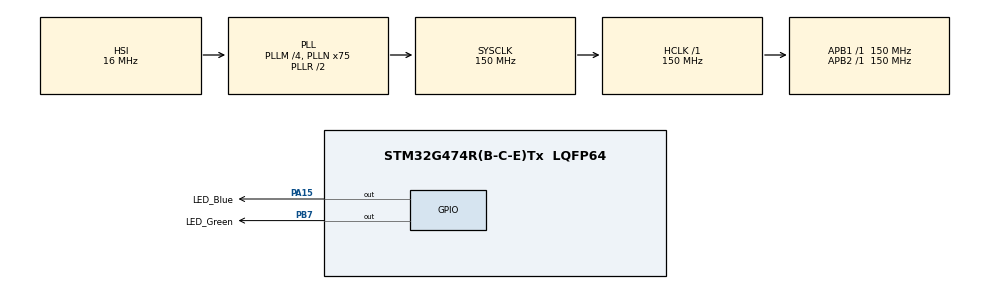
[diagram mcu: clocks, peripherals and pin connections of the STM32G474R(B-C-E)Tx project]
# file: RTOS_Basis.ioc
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FREERTOS.Tasks01=defaultTask,24,128,StartDefaultTask,Default,NULL,Dynamic,NULL,NULL
Mcu.Family=STM32G4
Mcu.Name=STM32G474R(B-C-E)Tx
Mcu.Package=LQFP64
NVIC.PriorityGroup=NVIC_PRIORITYGROUP_4
NVIC.TIM6_DAC_IRQn=true\:15\:0\:false\:false\:true\:false\:false\:true\:true
NVIC.TimeBase=TIM6_DAC_IRQn
NVIC.TimeBaseIP=TIM6
PA15.GPIO_Label=LED_Blue
PA15.Signal=GPIO_Output
PB7.GPIO_Label=LED_Green
PB7.Signal=GPIO_Output
ProjectManager.HeapSize=0x200
ProjectManager.StackSize=0x400
ProjectManager.TargetToolchain=STM32CubeIDE
RCC.ADC12Freq_Value=150000000
RCC.ADC345Freq_Value=150000000
RCC.AHBFreq_Value=150000000
RCC.APB1Freq_Value=150000000
RCC.APB1TimFreq_Value=150000000
RCC.APB2Freq_Value=150000000
RCC.APB2TimFreq_Value=150000000
RCC.CortexFreq_Value=150000000
RCC.EXTERNAL_CLOCK_VALUE=12288000
RCC.HCLKFreq_Value=150000000
RCC.HSE_VALUE=8000000
RCC.HSI48_VALUE=48000000
RCC.HSI_VALUE=16000000
RCC.LSE_VALUE=32768
RCC.PLLM=RCC_PLLM_DIV4
RCC.PLLN=75
RCC.SYSCLKFreq_VALUE=150000000
RCC.SYSCLKSource=RCC_SYSCLKSOURCE_PLLCLK
RCC.USBFreq_Value=150000000
RCC.VCOOutputFreq_Value=300000000
VP_FREERTOS_VS_CMSIS_V2.Mode=CMSIS_V2
VP_SYS_VS_DBSignals.Mode=DisableDeadBatterySignals
VP_SYS_VS_tim6.Mode=TIM6
board=custom

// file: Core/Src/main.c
/* USER CODE BEGIN Header */
/**
  ******************************************************************************
  * @file           : main.c
  * @brief          : Main program body
  ******************************************************************************
  * @attention
  *
  * Copyright (c) 2023 STMicroelectronics.
  * All rights reserved.
  *
  * This software is licensed under terms that can be found in the LICENSE file
  * in the root directory of this software component.
  * If no LICENSE file comes with this software, it is provided AS-IS.
  *
  ******************************************************************************
  */
/* USER CODE END Header */
#include "main.h"
#include "cmsis_os.h"

/* Definitions for defaultTask */
osThreadId_t defaultTaskHandle;
const osThreadAttr_t defaultTask_attributes = {
  .name = "defaultTask",
  .priority = (osPriority_t) osPriorityNormal,
  .stack_size = 128 * 4
};
/* USER CODE BEGIN PV */
#define DWT_CTRL (*(volatile uint32_t*) 0xE0001000)		// Bit 0 in this register can enable/disable the DWT_CYCCNT register
/* USER CODE END PV */

void SystemClock_Config(void);
static void MX_GPIO_Init(void);
void StartDefaultTask(void *argument);

/* USER CODE BEGIN PFP */
void vTaskLedBlue(void *pvParameters);
void vTaskLedGreen(void *pvParameters);
/* USER CODE END PFP */

int main(void)
{

  /* MCU Configuration--------------------------------------------------------*/

  /* Reset of all peripherals, Initializes the Flash interface and the Systick. */
  HAL_Init();

  /* Configure the system clock */
  SystemClock_Config();

  /* Initialize all configured peripherals */
  MX_GPIO_Init();

  /* Init scheduler */
  osKernelInitialize();

  /* Create the thread(s) */
  /* creation of defaultTask */
  //defaultTaskHandle = osThreadNew(StartDefaultTask, NULL, &defaultTask_attributes);

  /* USER CODE BEGIN RTOS_THREADS */
  // Enable the DWT_CYCCNT register (the cycle counter, to enable SEGGER time stamps)
  DWT_CTRL |= (1 << 0);

  SEGGER_SYSVIEW_Conf();
  SEGGER_SYSVIEW_Start();

  /* add threads, ... */
  // Blue LED task
  if((xTaskCreate(vTaskLedBlue, "Task LED Blue", configMINIMAL_STACK_SIZE, NULL, 1, NULL)) != pdTRUE)
  {

  }

  // Green LED task
  if((xTaskCreate(vTaskLedGreen, "Task LED Green", configMINIMAL_STACK_SIZE, NULL, 1, NULL)) != pdTRUE)
  {

  }
  /* USER CODE END RTOS_THREADS */

  /* Start scheduler */
  osKernelStart();

  /* We should never get here as control is now taken by the scheduler */
  /* Infinite loop */
  while (1)
  {

  }
}

void SystemClock_Config(void)
{
  RCC_OscInitTypeDef RCC_OscInitStruct = {0};
  RCC_ClkInitTypeDef RCC_ClkInitStruct = {0};

  /** Configure the main internal regulator output voltage
  */
  HAL_PWREx_ControlVoltageScaling(PWR_REGULATOR_VOLTAGE_SCALE1);

  /** Initializes the RCC Oscillators according to the specified parameters
  * in the RCC_OscInitTypeDef structure.
  */
  RCC_OscInitStruct.OscillatorType = RCC_OSCILLATORTYPE_HSI;
  RCC_OscInitStruct.HSIState = RCC_HSI_ON;
  RCC_OscInitStruct.HSICalibrationValue = RCC_HSICALIBRATION_DEFAULT;
  RCC_OscInitStruct.PLL.PLLState = RCC_PLL_ON;
  RCC_OscInitStruct.PLL.PLLSource = RCC_PLLSOURCE_HSI;
  RCC_OscInitStruct.PLL.PLLM = RCC_PLLM_DIV4;
  RCC_OscInitStruct.PLL.PLLN = 75;
  RCC_OscInitStruct.PLL.PLLP = RCC_PLLP_DIV2;
  RCC_OscInitStruct.PLL.PLLQ = RCC_PLLQ_DIV2;
  RCC_OscInitStruct.PLL.PLLR = RCC_PLLR_DIV2;
  if (HAL_RCC_OscConfig(&RCC_OscInitStruct) != HAL_OK)
  {
    Error_Handler();
  }

  /** Initializes the CPU, AHB and APB buses clocks
  */
  RCC_ClkInitStruct.ClockType = RCC_CLOCKTYPE_HCLK|RCC_CLOCKTYPE_SYSCLK
                              |RCC_CLOCKTYPE_PCLK1|RCC_CLOCKTYPE_PCLK2;
  RCC_ClkInitStruct.SYSCLKSource = RCC_SYSCLKSOURCE_PLLCLK;
  RCC_ClkInitStruct.AHBCLKDivider = RCC_SYSCLK_DIV1;
  RCC_ClkInitStruct.APB1CLKDivider = RCC_HCLK_DIV1;
  RCC_ClkInitStruct.APB2CLKDivider = RCC_HCLK_DIV1;

  if (HAL_RCC_ClockConfig(&RCC_ClkInitStruct, FLASH_LATENCY_4) != HAL_OK)
  {
    Error_Handler();
  }
}

static void MX_GPIO_Init(void)
{
  GPIO_InitTypeDef GPIO_InitStruct = {0};

  /* GPIO Ports Clock Enable */
  __HAL_RCC_GPIOA_CLK_ENABLE();
  __HAL_RCC_GPIOB_CLK_ENABLE();

  /*Configure GPIO pin Output Level */
  HAL_GPIO_WritePin(LED_Blue_GPIO_Port, LED_Blue_Pin, GPIO_PIN_RESET);

  /*Configure GPIO pin Output Level */
  HAL_GPIO_WritePin(LED_Green_GPIO_Port, LED_Green_Pin, GPIO_PIN_RESET);

  /*Configure GPIO pin : LED_Blue_Pin */
  GPIO_InitStruct.Pin = LED_Blue_Pin;
  GPIO_InitStruct.Mode = GPIO_MODE_OUTPUT_PP;
  GPIO_InitStruct.Pull = GPIO_NOPULL;
  GPIO_InitStruct.Speed = GPIO_SPEED_FREQ_LOW;
  HAL_GPIO_Init(LED_Blue_GPIO_Port, &GPIO_InitStruct);

  /*Configure GPIO pin : LED_Green_Pin */
  GPIO_InitStruct.Pin = LED_Green_Pin;
  GPIO_InitStruct.Mode = GPIO_MODE_OUTPUT_PP;
  GPIO_InitStruct.Pull = GPIO_NOPULL;
  GPIO_InitStruct.Speed = GPIO_SPEED_FREQ_LOW;
  HAL_GPIO_Init(LED_Green_GPIO_Port, &GPIO_InitStruct);

}

/* USER CODE BEGIN 4 */
void vTaskLedBlue(void *pvParameters)
{
	//Variable Declarations

	//Infinite Loop
	for(;;)
	{
		HAL_GPIO_TogglePin(LED_Blue_GPIO_Port, LED_Blue_Pin);
		vTaskDelay(1000 / portTICK_PERIOD_MS);
	}
	//Delete the task if the loop is broken
	vTaskDelete(NULL);
}

void vTaskLedGreen(void *pvParameters)
{
	//Variable Declarations

	//Infinite Loop
	for(;;)
	{
		HAL_GPIO_TogglePin(LED_Green_GPIO_Port, LED_Green_Pin);
		vTaskDelay(500 / portTICK_PERIOD_MS);
	}
	//Delete the task if the loop is broken
	vTaskDelete(NULL);
}
/* USER CODE END 4 */

void StartDefaultTask(void *argument)
{
  for(;;)
  {
    osDelay(1);
  }
}

void HAL_TIM_PeriodElapsedCallback(TIM_HandleTypeDef *htim)
{
  if (htim->Instance == TIM6) {
    HAL_IncTick();
  }
}

void Error_Handler(void)
{
  __disable_irq();
  while (1)
  {
  }
}
